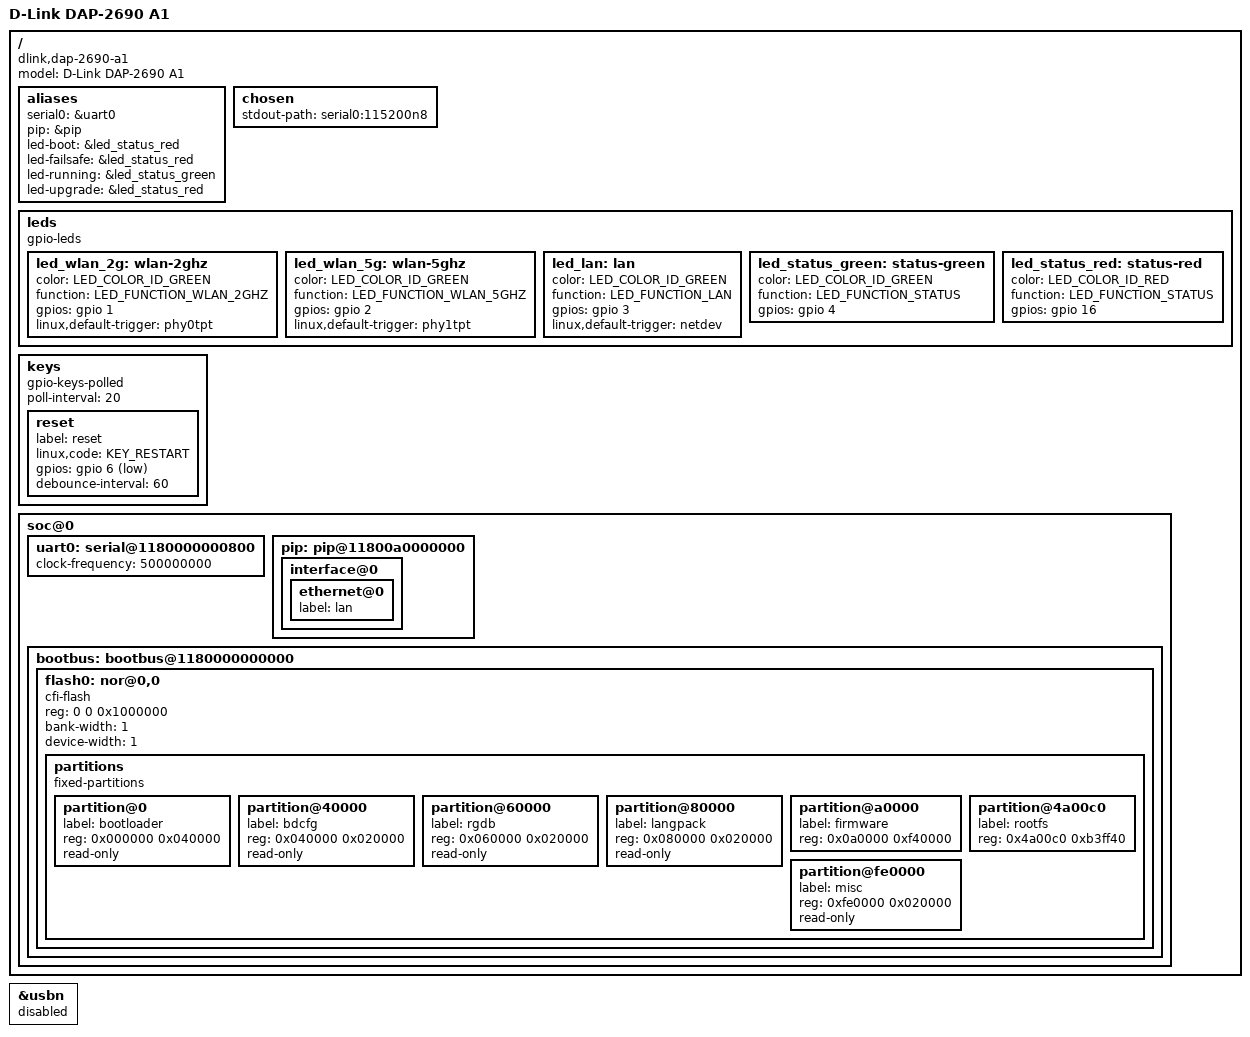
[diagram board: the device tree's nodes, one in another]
// SPDX-License-Identifier: GPL-2.0-or-later OR MIT

/include/ "octeon_3xxx.dtsi"
#include <dt-bindings/gpio/gpio.h>
#include <dt-bindings/input/input.h>
#include <dt-bindings/leds/common.h>

/ {
	compatible = "dlink,dap-2690-a1", "cavium,cn5010",
		     "cavium,octeon-3860";
	model = "D-Link DAP-2690 A1";

	aliases {
		serial0 = &uart0;
		pip = &pip;
		led-boot = &led_status_red;
		led-failsafe = &led_status_red;
		led-running = &led_status_green;
		led-upgrade = &led_status_red;
	};

	chosen {
		stdout-path = "serial0:115200n8";
	};

	leds {
		compatible = "gpio-leds";

		led_wlan_2g: wlan-2ghz {
			color = <LED_COLOR_ID_GREEN>;
			function = LED_FUNCTION_WLAN_2GHZ;
			gpios = <&gpio 1 GPIO_ACTIVE_HIGH>;
			linux,default-trigger = "phy0tpt";
		};

		led_wlan_5g: wlan-5ghz {
			color = <LED_COLOR_ID_GREEN>;
			function = LED_FUNCTION_WLAN_5GHZ;
			gpios = <&gpio 2 GPIO_ACTIVE_HIGH>;
			linux,default-trigger = "phy1tpt";
		};

		led_lan: lan {
			color = <LED_COLOR_ID_GREEN>;
			function = LED_FUNCTION_LAN;
			gpios = <&gpio 3 GPIO_ACTIVE_HIGH>;
			linux,default-trigger = "netdev";
		};

		led_status_green: status-green {
			color = <LED_COLOR_ID_GREEN>;
			function = LED_FUNCTION_STATUS;
			gpios = <&gpio 4 GPIO_ACTIVE_HIGH>;
		};

		led_status_red: status-red {
			color = <LED_COLOR_ID_RED>;
			function = LED_FUNCTION_STATUS;
			/*
			 * The factory kernel drives the red half of the status LED
			 * through extended GPIO 16.  GPIO 10 is used by the old
			 * manufacturing utility but does not control this LED on A1.
			 */
			gpios = <&gpio 16 GPIO_ACTIVE_HIGH>;
		};
	};

	keys {
		compatible = "gpio-keys-polled";
		poll-interval = <20>;

		reset {
			label = "reset";
			linux,code = <KEY_RESTART>;
			gpios = <&gpio 6 GPIO_ACTIVE_LOW>;
			debounce-interval = <60>;
		};
	};

	soc@0 {
		uart0: serial@1180000000800 {
			/* CN50XX I/O clock follows the 500 MHz core clock. */
			clock-frequency = <500000000>;
		};

		pip: pip@11800a0000000 {
			interface@0 {
				/delete-node/ ethernet@1;
				/delete-node/ ethernet@2;

				ethernet@0 {
					label = "lan";
				};
			};
		};

		bootbus: bootbus@1180000000000 {
			ranges = <0 0 0x0 0x1ec00000 0x1000000>;

			/* Preserve the timings programmed by the factory bootloader. */
			/delete-node/ cavium,cs-config@0;
			/delete-node/ cavium,cs-config@4;
			/delete-node/ cavium,cs-config@5;
			/delete-node/ cavium,cs-config@6;

			flash0: nor@0,0 {
				compatible = "cfi-flash";
				reg = <0 0 0x1000000>;
				bank-width = <1>;
				device-width = <1>;
				#address-cells = <1>;
				#size-cells = <1>;

				partitions {
					compatible = "fixed-partitions";
					#address-cells = <1>;
					#size-cells = <1>;

					partition@0 {
						label = "bootloader";
						reg = <0x000000 0x040000>;
						read-only;
					};

					partition@40000 {
						label = "bdcfg";
						reg = <0x040000 0x020000>;
						read-only;
					};

					partition@60000 {
						label = "rgdb";
						reg = <0x060000 0x020000>;
						read-only;
					};

					partition@80000 {
						label = "langpack";
						reg = <0x080000 0x020000>;
						read-only;
					};

					partition@a0000 {
						/*
						 * Complete D-Link V3 upgrade container.  This
						 * overlaps rootfs just like the vendor's dynamic
						 * "upgrade" partition does.
						 */
						label = "firmware";
						reg = <0x0a0000 0xf40000>;
					};

					partition@4a00c0 {
						/* D-Link headers + 0x400000 kernel area + tag. */
						label = "rootfs";
						reg = <0x4a00c0 0xb3ff40>;
					};

					partition@fe0000 {
						label = "misc";
						reg = <0xfe0000 0x020000>;
						read-only;
					};
				};
			};
		};
	};
};

&usbn {
	status = "disabled";
};
